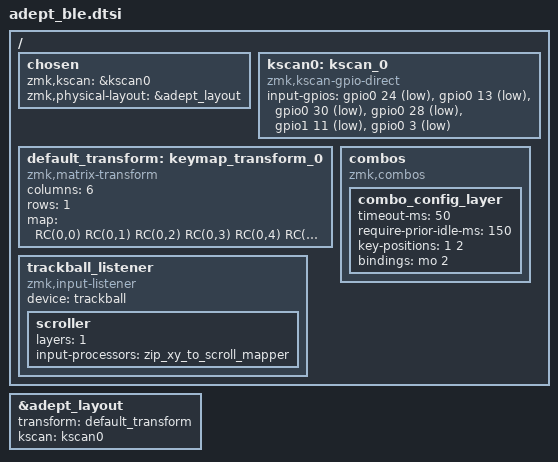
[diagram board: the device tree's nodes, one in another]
/*
 * Adept BLE shield：键盘本体定义
 *
 * 分工：
 *   本文件             按键扫描（kscan）与键位映射（transform）等结构
 *   adept_layout.dtsi  物理布局坐标（Studio / 画键位图用）
 *   adept_ble.overlay  轨迹球 SPI 设备
 *   adept_ble.keymap   各层键位
 *   adept_ble.conf     驱动与功能开关（Kconfig）
 *
 * SPDX-License-Identifier: MIT
 */

#include <dt-bindings/zmk/matrix_transform.h>
#include "adept_layout.dtsi"

/ {
	chosen {
		/* 按键数据来自哪个扫描设备 */
		zmk,kscan = &kscan0;
		/* 使用哪个物理布局（Studio 显示用） */
		zmk,physical-layout = &adept_layout;
	};

	/*
	 * 按键扫描：6 个按键直接接 IO，没有矩阵、没有二极管。
	 * 每个按键一端接 MCU 引脚、另一端接 GND，所以：
	 *   GPIO_ACTIVE_LOW  —— 按下时被拉到低电平，按“低有效”处理
	 *   GPIO_PULL_UP     —— 未按时靠内部上拉维持高电平，避免悬空误触发
	 *
	 * 这里的顺序就是「键位索引 0..5」，必须与下面 matrix_transform 的 RC 顺序、
	 * adept_layout.dtsi 的 keys 顺序、以及 keymap 每层的绑定顺序完全一致。
	 *
	 * 引脚来源（E73 焊盘 -> nRF 引脚）：
	 *   索引 0 左上大  焊盘 35 -> P0.24
	 *   索引 1 中左小  焊盘 33 -> P0.13
	 *   索引 2 中右小  焊盘 10 -> P0.30
	 *   索引 3 右上大  焊盘 4  -> P0.28
	 *   索引 4 左下    焊盘 1  -> P1.11
	 *   索引 5 右下    焊盘 3  -> P0.03
	 *
	 * 注意最后两个：物理左下的键接在 P1.11、物理右下的键接在 P0.03，
	 * 所以这里 P1.11 在前（索引 4 = 左）、P0.03 在后（索引 5 = 右）。
	 * 若日后发现左右又反了，把这两条对调即可（不要动键值）。
	 */
	kscan0: kscan_0 {
		compatible = "zmk,kscan-gpio-direct";

		input-gpios
			= <&gpio0 24 (GPIO_ACTIVE_LOW | GPIO_PULL_UP)>   /* 索引0 左上大  P0.24 */
			, <&gpio0 13 (GPIO_ACTIVE_LOW | GPIO_PULL_UP)>   /* 索引1 中左小  P0.13 */
			, <&gpio0 30 (GPIO_ACTIVE_LOW | GPIO_PULL_UP)>   /* 索引2 中右小  P0.30 */
			, <&gpio0 28 (GPIO_ACTIVE_LOW | GPIO_PULL_UP)>   /* 索引3 右上大  P0.28 */
			, <&gpio1 11 (GPIO_ACTIVE_LOW | GPIO_PULL_UP)>   /* 索引4 左下    P1.11 */
			, <&gpio0 3  (GPIO_ACTIVE_LOW | GPIO_PULL_UP)>   /* 索引5 右下    P0.03 */
			;
	};

	/*
	 * 键位映射表：把“扫描到的物理位置”映射成“第几个键”。
	 * 6 个按键所以是 6 列的虚拟矩阵，行数为 1。
	 * 条目数（6）必须等于 keymap 每层的绑定数（6）。
	 */
	default_transform: keymap_transform_0 {
		compatible = "zmk,matrix-transform";
		columns = <6>;
		rows = <1>;

		map = <
			RC(0,0) RC(0,1) RC(0,2) RC(0,3) RC(0,4) RC(0,5)
		>;
	};

	/*
	 * 轨迹球数据入口。
	 *
	 * PMW3610 驱动上报标准 input 事件，由本监听器接进 ZMK 的指针处理流程。
	 * 正常情况下这些事件被当作指针位移发送给主机；
	 * 当第 1 层（滚动层）被激活时，下面的 scroller 覆盖节点会改用
	 * &zip_xy_to_scroll_mapper，把 X/Y 位移转成滚轮 / 横向滚轮事件。
	 *
	 * 覆盖节点的规则（官方文档 keymaps/input-processors/usage）：
	 *   - layers 列出的层「也在激活集合里」时，该覆盖生效
	 *   - 默认第一个匹配的覆盖生效后，就不再走基础处理器（父节点的）
	 *   - 因为 &tog 1 / &mo 1 只是额外激活第 1 层，第 0 层仍然激活，
	 *     所以滚动模式下六个按键照常可用
	 */
	trackball_listener {
		compatible = "zmk,input-listener";
		device = <&trackball>;

		scroller {
			layers = <1>;
			input-processors = <&zip_xy_to_scroll_mapper>;
		};
	};

	/*
	 * 组合键：同时按住「中左小键」与「中右小键」进入第 2 层（配置层），
	 * 松开任意一个即退出，回到默认层。
	 *
	 * key-positions 用的是键位索引，从 0 开始，与 keymap 每层绑定顺序一致：
	 *   0 左上大   1 中左小   2 中右小   3 右上大   4 左下   5 右下
	 *
	 * timeout-ms：两个键必须在这个时间内先后按下才算组合。
	 * require-prior-idle-ms：若在这段时间内刚按过别的键，则不触发组合，
	 * 避免正常点击时被误判。
	 */
	combos {
		compatible = "zmk,combos";

		combo_config_layer {
			timeout-ms = <50>;
			require-prior-idle-ms = <150>;
			key-positions = <1 2>;
			bindings = <&mo 2>;
		};
	};
};

/* 把 transform 与 kscan 关联到物理布局节点上（ZMK 布局体系的要求） */
&adept_layout {
	transform = <&default_transform>;
	kscan = <&kscan0>;
};
